# R7FA2E2A7 register map
Vendor: Renesas Electronics Corporation; Series: RA2; File version: 1.10.02
CPU: CM23 r1p0, little endian, MPU, no FPU, VTOR, 2 interrupt priority bits, 32 interrupts
Registers are 32-bit, read-write, reset 0x0 unless marked. A register's access mark holds for its fields unless they carry their own. Offsets are from the block's base; [hi:lo] are bit positions; {n}, {i} and the like mark numbered series; 'fields as' and 'values as' point back to an identical list.

## PFS — Pmn Pin Function Control Register
Base 0x40040800
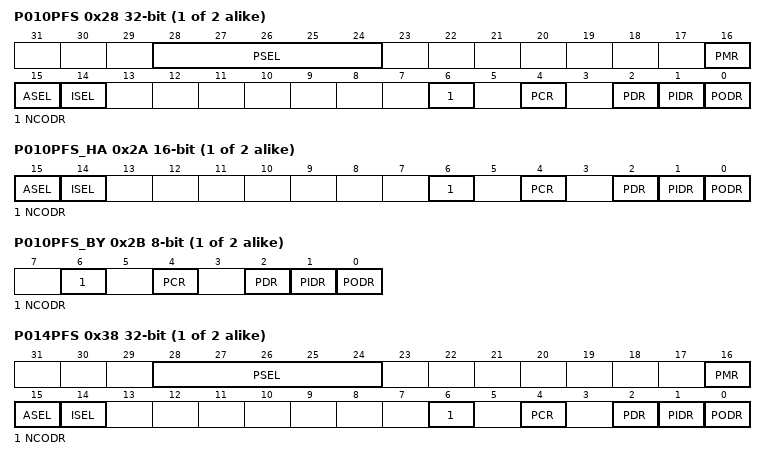
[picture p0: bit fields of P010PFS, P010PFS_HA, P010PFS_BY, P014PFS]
{0x0+4i} P0{i}PFS (i=10..11) (reset mask 0xFFFFFFFD) — Port 0{i} Pin Function Select Register
  [28:24] PSEL — Peripheral Select
  [16] PMR — Port Mode Control
    0=Use as general I/O pin; 1=Use as I/O port for peripheral functions
  [15] ASEL — Analog Input Enable
    0=Do not use as analog pin; 1=Use as analog pin
  [14] ISEL — IRQ Input Enable
    0=Do not use as IRQn input pin; 1=Use as IRQn input pin
  [6] NCODR — N-Channel Open-Drain Control
    0=Output CMOS; 1=Output NMOS open-drain
  [4] PCR — Pull-up Control
    0=Disable input pull-up; 1=Enable input pull-up
  [2] PDR — Port Direction
    0=Input (functions as an input pin); 1=Output (functions as an output pin)
  [1] PIDR ro — Port State
    0=Low level; 1=High level
  [0] PODR — Port Output Data
    0=Output low; 1=Output high
{0x2+4i} P0{i}PFS_HA (i=10..11) 16-bit (reset mask 0xFFFD) (alternate view of P0{i}PFS) — Port 0{i} Pin Function Select Register
  [15] ASEL — Analog Input Enable
    0=Do not use as analog pin; 1=Use as analog pin
  [14] ISEL — IRQ Input Enable
    0=Do not use as IRQn input pin; 1=Use as IRQn input pin
  [6] NCODR — N-Channel Open-Drain Control
    0=Output CMOS; 1=Output NMOS open-drain
  [4] PCR — Pull-up Control
    0=Disable input pull-up; 1=Enable input pull-up
  [2] PDR — Port Direction
    values as P010PFS.PDR
  [1] PIDR ro — Port State
    0=Low level; 1=High level
  [0] PODR — Port Output Data
    0=Output low; 1=Output high
{0x3+4i} P0{i}PFS_BY (i=10..11) 8-bit (reset mask 0xFD) (alternate view of P0{i}PFS) — Port 0{i} Pin Function Select Register
  [6] NCODR — N-Channel Open-Drain Control
    0=Output CMOS; 1=Output NMOS open-drain
  [4] PCR — Pull-up Control
    0=Disable input pull-up; 1=Enable input pull-up
  [2] PDR — Port Direction
    values as P010PFS.PDR
  [1] PIDR ro — Port State
    0=Low level; 1=High level
  [0] PODR — Port Output Data
    0=Output low; 1=Output high
{0x0+4i} P0{i}PFS (i=14..15) (reset mask 0xFFFFFFFD) — Port 0{i} Pin Function Select Register
  fields as P010PFS
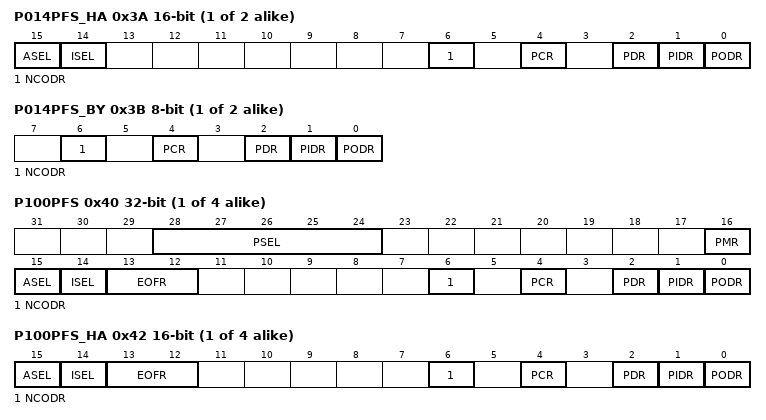
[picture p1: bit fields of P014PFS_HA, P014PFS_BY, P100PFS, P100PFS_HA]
{0x2+4i} P0{i}PFS_HA (i=14..15) 16-bit (reset mask 0xFFFD) (alternate view of P0{i}PFS) — Port 0{i} Pin Function Select Register
  fields as P010PFS_HA
{0x3+4i} P0{i}PFS_BY (i=14..15) 8-bit (reset mask 0xFD) (alternate view of P0{i}PFS) — Port 0{i} Pin Function Select Register
  fields as P010PFS_BY
{0x40+4i} P10{i}PFS (i=0..3) (reset mask 0xFFFFFFFD) — Port 10{i} Pin Function Select Register
  [28:24] PSEL — Peripheral Select
  [16] PMR — Port Mode Control
    values as P010PFS.PMR
  [15] ASEL — Analog Input Enable
    0=Do not use as analog pin; 1=Use as analog pin
  [14] ISEL — IRQ Input Enable
    0=Do not use as IRQn input pin; 1=Use as IRQn input pin
  [13:12] EOFR — Event on Falling/Event on Rising
    0=Don't care; 1=Detect rising edge; 2=Detect falling edge; 3=Detect both edges
  [6] NCODR — N-Channel Open-Drain Control
    0=Output CMOS; 1=Output NMOS open-drain
  [4] PCR — Pull-up Control
    0=Disable input pull-up; 1=Enable input pull-up
  [2] PDR — Port Direction
    values as P010PFS.PDR
  [1] PIDR ro — Port State
    0=Low level; 1=High level
  [0] PODR — Port Output Data
    0=Output low; 1=Output high
{0x42+4i} P10{i}PFS_HA (i=0..3) 16-bit (reset mask 0xFFFD) (alternate view of P10{i}PFS) — Port 10{i} Pin Function Select Register
  [15] ASEL — Analog Input Enable
    0=Do not use as analog pin; 1=Use as analog pin
  [14] ISEL — IRQ Input Enable
    0=Do not use as IRQn input pin; 1=Use as IRQn input pin
  [13:12] EOFR — Event on Falling/Event on Rising
    values as P100PFS.EOFR
  [6] NCODR — N-Channel Open-Drain Control
    0=Output CMOS; 1=Output NMOS open-drain
  [4] PCR — Pull-up Control
    0=Disable input pull-up; 1=Enable input pull-up
  [2] PDR — Port Direction
    values as P010PFS.PDR
  [1] PIDR ro — Port State
    0=Low level; 1=High level
  [0] PODR — Port Output Data
    0=Output low; 1=Output high
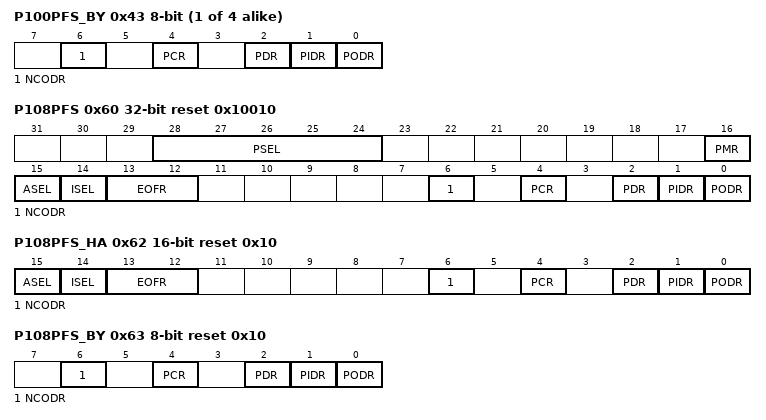
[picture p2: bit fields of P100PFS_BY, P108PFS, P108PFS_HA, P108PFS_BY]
{0x43+4i} P10{i}PFS_BY (i=0..3) 8-bit (reset mask 0xFD) (alternate view of P10{i}PFS) — Port 10{i} Pin Function Select Register
  fields as P010PFS_BY
0x60 P108PFS reset 0x10010 (reset mask 0xFFFFFFFD) — Port 108 Pin Function Select Register
  fields as P100PFS
0x62 P108PFS_HA 16-bit reset 0x10 (reset mask 0xFFFD) (alternate view of P108PFS) — Port 108 Pin Function Select Register
  fields as P100PFS_HA
0x63 P108PFS_BY 8-bit reset 0x10 (reset mask 0xFD) (alternate view of P108PFS) — Port 108 Pin Function Select Register
  fields as P010PFS_BY
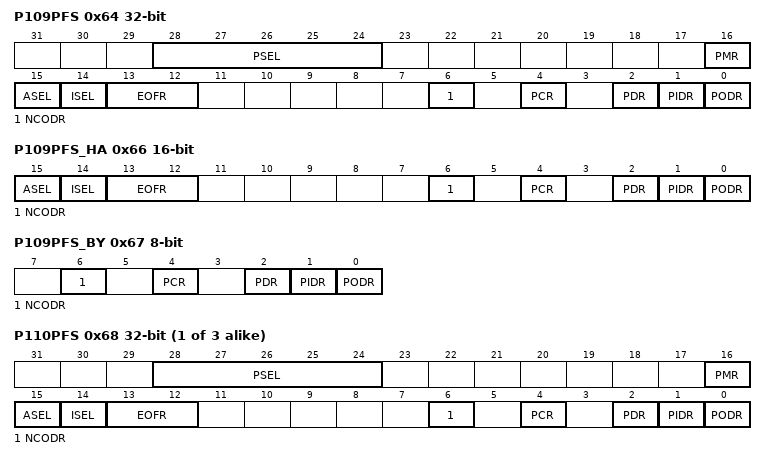
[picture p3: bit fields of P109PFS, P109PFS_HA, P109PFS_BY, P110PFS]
0x64 P109PFS (reset mask 0xFFFFFFFD) — Port 109 Pin Function Select Register
  fields as P100PFS
0x66 P109PFS_HA 16-bit (reset mask 0xFFFD) (alternate view of P109PFS) — Port 109 Pin Function Select Register
  fields as P100PFS_HA
0x67 P109PFS_BY 8-bit (reset mask 0xFD) (alternate view of P109PFS) — Port 109 Pin Function Select Register
  fields as P010PFS_BY
{0x40+4i} P1{i}PFS (i=10..12) (reset mask 0xFFFFFFFD) — Port 1{i} Pin Function Select Register
  fields as P100PFS
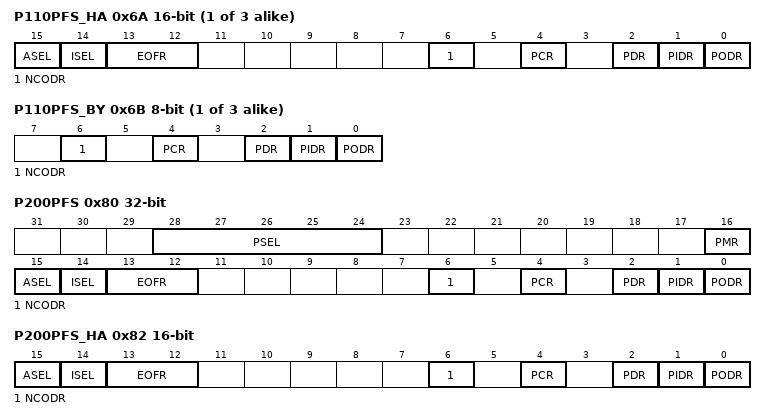
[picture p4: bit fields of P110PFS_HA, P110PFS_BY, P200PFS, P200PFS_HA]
{0x42+4i} P1{i}PFS_HA (i=10..12) 16-bit (reset mask 0xFFFD) (alternate view of P1{i}PFS) — Port 1{i} Pin Function Select Register
  fields as P100PFS_HA
{0x43+4i} P1{i}PFS_BY (i=10..12) 8-bit (reset mask 0xFD) (alternate view of P1{i}PFS) — Port 1{i} Pin Function Select Register
  fields as P010PFS_BY
0x80 P200PFS (reset mask 0xFFFFFFFD) — Port 200 Pin Function Select Register
  fields as P100PFS
0x82 P200PFS_HA 16-bit (reset mask 0xFFFD) (alternate view of P200PFS) — Port 200 Pin Function Select Register
  fields as P100PFS_HA
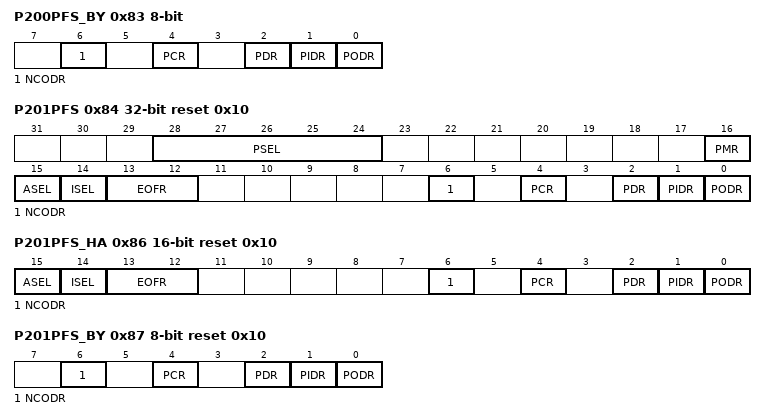
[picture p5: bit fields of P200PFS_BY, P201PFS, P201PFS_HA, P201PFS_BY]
0x83 P200PFS_BY 8-bit (reset mask 0xFD) (alternate view of P200PFS) — Port 200 Pin Function Select Register
  fields as P010PFS_BY
0x84 P201PFS reset 0x10 (reset mask 0xFFFFFFFD) — Port 201 Pin Function Select Register
  fields as P100PFS
0x86 P201PFS_HA 16-bit reset 0x10 (reset mask 0xFFFD) (alternate view of P201PFS) — Port 201 Pin Function Select Register
  fields as P100PFS_HA
0x87 P201PFS_BY 8-bit reset 0x10 (reset mask 0xFD) (alternate view of P201PFS) — Port 201 Pin Function Select Register
  fields as P010PFS_BY
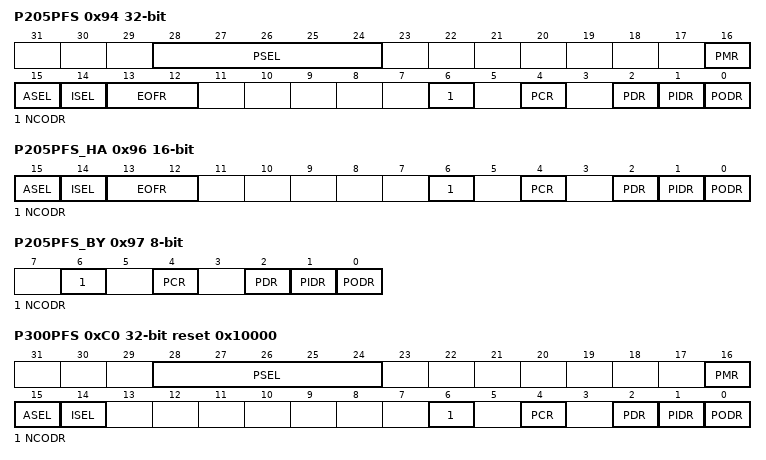
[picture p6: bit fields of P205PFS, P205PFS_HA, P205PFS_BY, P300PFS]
0x94 P205PFS (reset mask 0xFFFFFFFD) — Port 205 Pin Function Select Register
  fields as P100PFS
0x96 P205PFS_HA 16-bit (reset mask 0xFFFD) (alternate view of P205PFS) — Port 205 Pin Function Select Register
  fields as P100PFS_HA
0x97 P205PFS_BY 8-bit (reset mask 0xFD) (alternate view of P205PFS) — Port 205 Pin Function Select Register
  fields as P010PFS_BY
0xC0 P300PFS reset 0x10000 (reset mask 0xFFFFFFFD) — Port 300 Pin Function Select Register
  fields as P010PFS
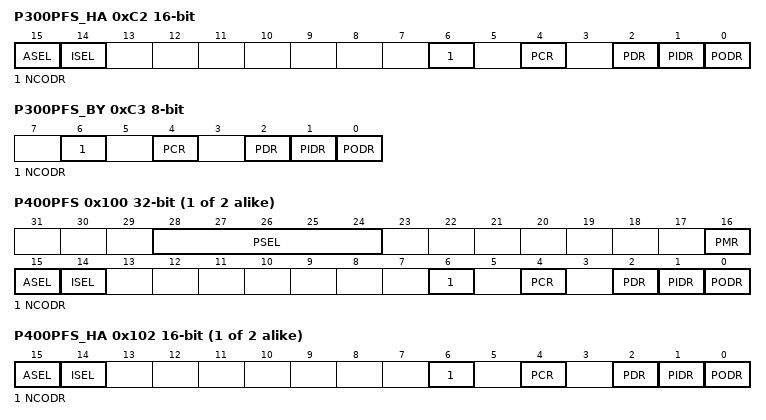
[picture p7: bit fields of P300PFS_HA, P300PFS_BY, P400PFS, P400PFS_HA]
0xC2 P300PFS_HA 16-bit (reset mask 0xFFFD) (alternate view of P300PFS) — Port 300 Pin Function Select Register
  fields as P010PFS_HA
0xC3 P300PFS_BY 8-bit (reset mask 0xFD) (alternate view of P300PFS) — Port 300 Pin Function Select Register
  fields as P010PFS_BY
{0x100+4i} P40{i}PFS (i=0..1) (reset mask 0xFFFFFFFD) — Port 40{i} Pin Function Select Register
  fields as P010PFS
{0x102+4i} P40{i}PFS_HA (i=0..1) 16-bit (reset mask 0xFFFD) (alternate view of P40{i}PFS) — Port 40{i} Pin Function Select Register
  fields as P010PFS_HA
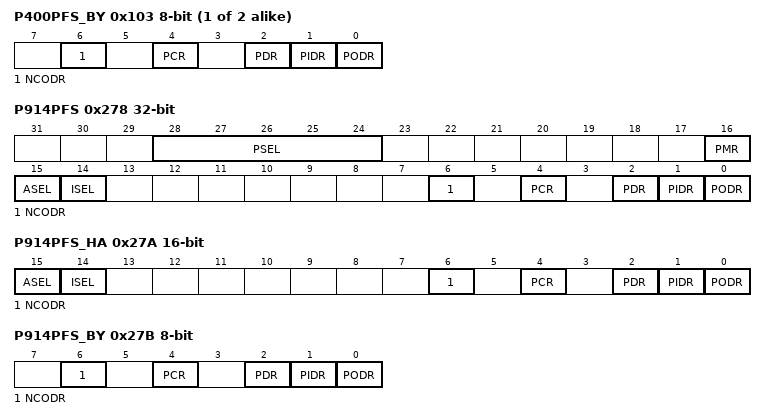
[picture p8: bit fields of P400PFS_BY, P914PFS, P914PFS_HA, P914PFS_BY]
{0x103+4i} P40{i}PFS_BY (i=0..1) 8-bit (reset mask 0xFD) (alternate view of P40{i}PFS) — Port 40{i} Pin Function Select Register
  fields as P010PFS_BY
0x278 P914PFS (reset mask 0xFFFFFFFD) — Port 914 Pin Function Select Register
  fields as P010PFS
0x27A P914PFS_HA 16-bit (reset mask 0xFFFD) (alternate view of P914PFS) — Port 914 Pin Function Select Register
  fields as P010PFS_HA
0x27B P914PFS_BY 8-bit (reset mask 0xFD) (alternate view of P914PFS) — Port 914 Pin Function Select Register
  fields as P010PFS_BY
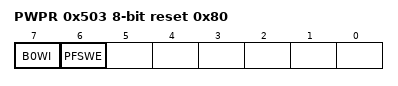
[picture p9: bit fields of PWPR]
0x503 PWPR 8-bit reset 0x80 — Write-Protect Register
  [7] B0WI — PFSWE Bit Write Disable
    0=Writing to the PFSWE bit is enabled; 1=Writing to the PFSWE bit is disabled
  [6] PFSWE — PmnPFS Register Write Enable
    0=Writing to the PmnPFS register is disabled; 1=Writing to the PmnPFS register is enabled
0x50F PRWCNTR 8-bit reset 0x1 — Port Read Wait Control Register
  [1:0] WAIT — Wait Cycle Control
    0=Setting prohibited; 1=Insert a 1-cycle wait; 2=Insert a 2-cycle wait; 3=Insert a 3-cycle wait

## Notices in the file
This software is supplied by Renesas Electronics Corporation and is only intended for
use with Renesas products. No other uses are authorized. This software is owned by
Renesas Electronics Corporation and is protected under all applicable laws, including
copyright laws.
THIS SOFTWARE IS PROVIDED "AS IS" AND RENESAS MAKES NO WARRANTIES REGARDING
THIS SOFTWARE, WHETHER EXPRESS, IMPLIED OR STATUTORY, INCLUDING BUT NOT LIMITED TO
WARRANTIES OF MERCHANTABILITY, FITNESS FOR A PARTICULAR PURPOSE AND NON-INFRINGEMENT.
ALL SUCH WARRANTIES ARE EXPRESSLY DISCLAIMED. TO THE MAXIMUM EXTENT PERMITTED NOT
PROHIBITED BY LAW, NEITHER RENESAS ELECTRONICS CORPORATION NOR ANY OF ITS AFFILIATED
COMPANIES SHALL BE LIABLE FOR ANY DIRECT, INDIRECT, SPECIAL, INCIDENTAL OR CONSEQUENTIAL
DAMAGES FOR ANY REASON RELATED TO THIS SOFTWARE, EVEN IF RENESAS OR ITS AFFILIATES HAVE
BEEN ADVISED OF THE POSSIBILITY OF SUCH DAMAGES.
Renesas reserves the right, without notice, to make changes to this software and to
discontinue the availability of this software. By using this software, you agree to
the additional terms and conditions found by accessing the following link:
http://www.renesas.com/disclaimer
